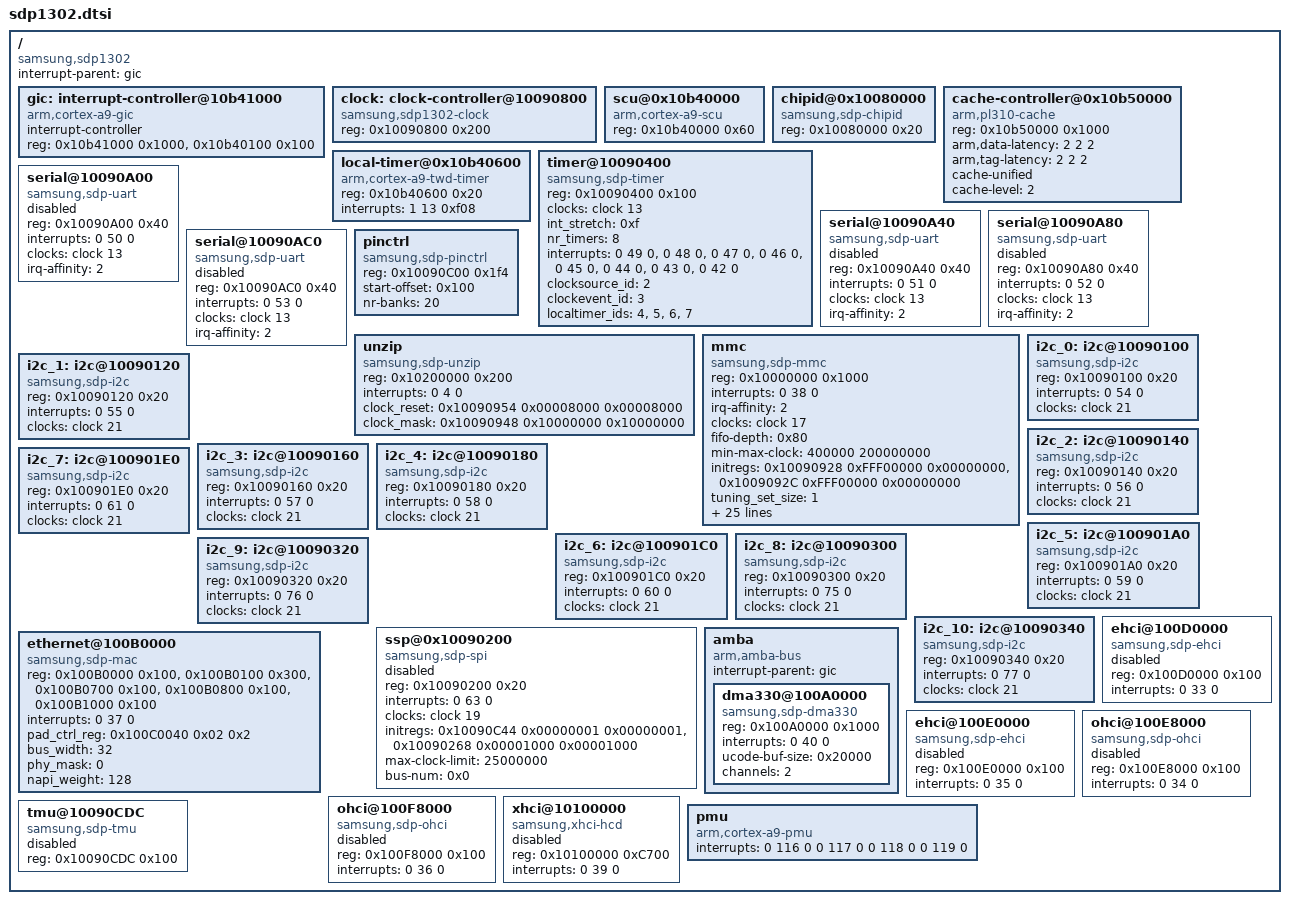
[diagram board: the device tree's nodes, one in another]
/*
 * Copyright (C) 2013 Samsung Electronics Co.Ltd
 *
 * This program is free software; you can redistribute it and/or modify
 * it under the terms of the GNU General Public License version 2 as
 * published by the Free Software Foundation.
 */

#include "sdp.dtsi"
#include "sdp1302-pinctrl.dtsi"

/ {
	compatible = "samsung,sdp1302";

	interrupt-parent = <&gic>;

	gic: interrupt-controller@10b41000 {
		compatible = "arm,cortex-a9-gic";
		interrupt-controller;
		#interrupt-cells = <3>;
		reg = <0x10b41000 0x1000>, <0x10b40100 0x100>;
	};

	clock: clock-controller@10090800 {
		compatible = "samsung,sdp1302-clock";
		reg = <0x10090800 0x200>;
		#clock-cells = <1>;
	};
        
	scu@0x10b40000 {
		compatible = "arm,cortex-a9-scu";
		reg = <0x10b40000 0x60>;
	};

	chipid@0x10080000 {
		compatible = "samsung,sdp-chipid";
		reg = <0x10080000 0x20>;
	};

	cache-controller@0x10b50000 {
		compatible = "arm,pl310-cache";
		reg = <0x10b50000 0x1000>;
		arm,data-latency = <2 2 2>;
		arm,tag-latency = <2 2 2>;
		cache-unified;
		cache-level = <2>;
	};

	local-timer@0x10b40600 {
		compatible = "arm,cortex-a9-twd-timer";
		reg = <0x10b40600 0x20>;
		interrupts = <1 13 0xf08>;
	};

	timer@10090400 {
		compatible = "samsung,sdp-timer";
		reg = <0x10090400 0x100>;
		clocks = <&clock 13>;
		clock-names = "apb_pclk";
		int_stretch = <0xf>;
		nr_timers = <8>;
		interrupts = <0 49 0>, <0 48 0>, <0 47 0>, <0 46 0>,
			<0 45 0>, <0 44 0>, <0 43 0>, <0 42 0>;
		clocksource_id = <2>;
		clockevent_id = <3>;
		localtimer_ids = <4>, <5>, <6>, <7>;
	};

	serial@10090A00 {
		compatible = "samsung,sdp-uart";
		reg = <0x10090A00 0x40>;
		interrupts = <0 50 0>;
		clocks = <&clock 13>;
		clock-names = "apb_pclk";
		irq-affinity = <2>;
		status = "disabled";
	};

	serial@10090A40 {
		compatible = "samsung,sdp-uart";
		reg = <0x10090A40 0x40>;
		interrupts = <0 51 0>;
		clocks = <&clock 13>;
		clock-names = "apb_pclk";
		irq-affinity = <2>;
		status = "disabled";
	};

	serial@10090A80 {
		compatible = "samsung,sdp-uart";
		reg = <0x10090A80 0x40>;
		interrupts = <0 52 0>;
		clocks = <&clock 13>;
		clock-names = "apb_pclk";
		irq-affinity = <2>;
		status = "disabled";
	};

	serial@10090AC0 {
		compatible = "samsung,sdp-uart";
		reg = <0x10090AC0 0x40>;
		interrupts = <0 53 0>;
		clocks = <&clock 13>;
		clock-names = "apb_pclk";
		irq-affinity = <2>;
		status = "disabled";
	};

	pinctrl {
		compatible = "samsung,sdp-pinctrl";
		reg = <0x10090C00 0x1f4>;
		start-offset = <0x100>;
		nr-banks = <20> ;
	};

	unzip {
		compatible = "samsung,sdp-unzip";
		reg = <0x10200000 0x200>;
		interrupts = < 0 4 0 >;
		clock_reset = <0x10090954 0x00008000 0x00008000>; 
		clock_mask = <0x10090948 0x10000000 0x10000000>;
	};
	
	mmc {
		compatible = "samsung,sdp-mmc";
		reg = <0x10000000 0x1000>;
		interrupts = <0 38 0>;
		irq-affinity = <2>;
		clocks = <&clock 17>;
		clock-names = "emmc_clk";
		fifo-depth = <0x80>;
		min-max-clock = <400000 200000000>;
		initregs =	<0x10090928 0xFFF00000 0x00000000>, <0x1009092C 0xFFF00000 0x00000000>;/* sam, drv bypass */

//		restoreregs =	<0x10090928 0xFFF00000>,/* eMMC drv delay register */
//						<0x1009092C 0xFFF00000>;/* eMMC sam delay register */

		/* eMMC Sampling Clock Delay Selection. 1.25ns ~ 5ns for HS200 */
		tuning_set_size = <1>;
		tuning_sam =	<0x1009092C 0xFFF00000 0x00800000>,
						<0x1009092C 0xFFF00000 0x04800000>,
						<0x1009092C 0xFFF00000 0x08800000>,
						<0x1009092C 0xFFF00000 0x0C800000>,
						<0x1009092C 0xFFF00000 0x01000000>,
						<0x1009092C 0xFFF00000 0x11000000>,
						<0x1009092C 0xFFF00000 0x21000000>,
						<0x1009092C 0xFFF00000 0x31000000>,
						<0x1009092C 0xFFF00000 0x01800000>,
						<0x1009092C 0xFFF00000 0x41800000>,
						<0x1009092C 0xFFF00000 0x81800000>,
						<0x1009092C 0xFFF00000 0xC1800000>,
						<0x1009092C 0xFFF00000 0x02000000>,
						<0x1009092C 0xFFF00000 0x42000000>;
						//<0x1009092C 0xFFF00000 0x82000000>,
						//<0x1009092C 0xFFF00000 0xC2000000>,
						//<0x1009092C 0xFFF00000 0x02800000>,
						//<0x1009092C 0xFFF00000 0x42800000>,
						//<0x1009092C 0xFFF00000 0x82800000>,
						//<0x1009092C 0xFFF00000 0xC2800000>;

		tuning_sam_hs200_default = <0x1009092C 0xFFF00000 0x00800000>;/* HS200 sampling defalut */
		tuning_drv_hs200_default = <0x10090928 0xFFF00000 0x04800000>;/* HS200 driving defalut for rev1 */
		fixup-golfs-input-clock;


		bus-width = <0x8>;
//		force-pio-mode;
		hw-reset;

		/* Host Caps */
		non-removable;
//		bus-width-test;
		highspeed;
//		sdr104;
		ddr50;
//		hs200;
		hs200-tuning;
	};

	i2c_0: i2c@10090100 {
		#address-cells = <1>;
		#size-cells = <0>;
		compatible = "samsung,sdp-i2c";
		reg = <0x10090100 0x20>;
		interrupts = <0 54 0>;
		clocks = <&clock 21>;
		clock-names = "rstn_i2c";
	};

	i2c_1: i2c@10090120 {
		#address-cells = <1>;
		#size-cells = <0>;
		compatible = "samsung,sdp-i2c";
		reg = <0x10090120 0x20>;
		interrupts = <0 55 0>;
		clocks = <&clock 21>;
		clock-names = "rstn_i2c";
	};

	i2c_2: i2c@10090140 {
		#address-cells = <1>;
		#size-cells = <0>;
		compatible = "samsung,sdp-i2c";
		reg = <0x10090140 0x20>;
		interrupts = <0 56 0>;
		clocks = <&clock 21>;
		clock-names = "rstn_i2c";
	};

	i2c_3: i2c@10090160 {
		#address-cells = <1>;
		#size-cells = <0>;
		compatible = "samsung,sdp-i2c";
		reg = <0x10090160 0x20>;
		interrupts = <0 57 0>;
		clocks = <&clock 21>;
		clock-names = "rstn_i2c";
	};

	i2c_4: i2c@10090180 {
		#address-cells = <1>;
		#size-cells = <0>;
		compatible = "samsung,sdp-i2c";
		reg = <0x10090180 0x20>;
		interrupts = <0 58 0>;
		clocks = <&clock 21>;
		clock-names = "rstn_i2c";
	};

	i2c_5: i2c@100901A0 {
		#address-cells = <1>;
		#size-cells = <0>;
		compatible = "samsung,sdp-i2c";
		reg = <0x100901A0 0x20>;
		interrupts = <0 59 0>;
		clocks = <&clock 21>;
		clock-names = "rstn_i2c";
	};

	i2c_6: i2c@100901C0 {
		#address-cells = <1>;
		#size-cells = <0>;
		compatible = "samsung,sdp-i2c";
		reg = <0x100901C0 0x20>;
		interrupts = <0 60 0>;
		clocks = <&clock 21>;
		clock-names = "rstn_i2c";
	};

	i2c_7: i2c@100901E0 {
		#address-cells = <1>;
		#size-cells = <0>;
		compatible = "samsung,sdp-i2c";
		reg = <0x100901E0 0x20>;
		interrupts = <0 61 0>;
		clocks = <&clock 21>;
		clock-names = "rstn_i2c";
	};

	i2c_8: i2c@10090300 {
		#address-cells = <1>;
		#size-cells = <0>;
		compatible = "samsung,sdp-i2c";
		reg = <0x10090300 0x20>;
		interrupts = <0 75 0>;
		clocks = <&clock 21>;
		clock-names = "rstn_i2c";
	};

	i2c_9: i2c@10090320 {
		#address-cells = <1>;
		#size-cells = <0>;
		compatible = "samsung,sdp-i2c";
		reg = <0x10090320 0x20>;
		interrupts = <0 76 0>;
		clocks = <&clock 21>;
		clock-names = "rstn_i2c";
	};

	i2c_10: i2c@10090340 {
		#address-cells = <1>;
		#size-cells = <0>;
		compatible = "samsung,sdp-i2c";
		reg = <0x10090340 0x20>;
		interrupts = <0 77 0>;
		clocks = <&clock 21>;
		clock-names = "rstn_i2c";
	};

	ssp@0x10090200 {
		status = "disable";
		compatible = "samsung,sdp-spi";
		reg = <0x10090200 0x20>;
		interrupts = <0 63 0>;
		clocks = <&clock 19>;
		clock-names = "spi_clk";

		#address-cells = <1>;
		#size-cells = <0>;

		initregs =	<0x10090C44 0x00000001 0x00000001>,/* SUB_FUNC_SEL_REG0 bit0 Pad SPI_SEL Selection */
					<0x10090268 0x00001000 0x00001000>;/* change MSPI to SSP */
		max-clock-limit = <25000000>;
		bus-num = <0x0>;
	};

	amba {
		#address-cells = <1>;
		#size-cells = <1>;
		compatible = "arm,amba-bus";
		interrupt-parent = <&gic>;
		ranges;

		dma330@100A0000 {
			status = "okay";
			compatible = "samsung,sdp-dma330", "arm,primecell";
			reg = <0x100A0000 0x1000>;
			interrupts = <0 40 0>;

			ucode-buf-size = <0x20000>;/*128kb*/
			channels = <2>;
		};
	};

	ethernet@100B0000 {
		compatible = "samsung,sdp-mac";
		reg = <0x100B0000 0x100>,
			<0x100B0100 0x300>,
			<0x100B0700 0x100>,
			<0x100B0800 0x100>,
			<0x100B1000 0x100>;
		interrupts = <0 37 0>;
		pad_ctrl_reg = <0x100C0040 0x02 0x2>;/* sstone sel */
		bus_width = <32>;
		phy_mask = <0>;
		napi_weight = <128>;
	};

	ehci@100D0000 {
		compatible = "samsung,sdp-ehci", "usb-ehci";
		reg = <0x100D0000 0x100>;
		interrupts = <0 33 0>;
		status = "disabled";
	};

	ehci@100E0000 {
		compatible = "samsung,sdp-ehci", "usb-ehci";
		reg = <0x100E0000 0x100>;
		interrupts = <0 35 0>;
		status = "disabled";
	};

	ohci@100E8000 {
		compatible = "samsung,sdp-ohci", "usb-ohci";
		reg = <0x100E8000 0x100>;
		interrupts = <0 34 0>;
		status = "disabled";
	};

	ohci@100F8000 {
		compatible = "samsung,sdp-ohci", "usb-ohci";
		reg = <0x100F8000 0x100>;
		interrupts = <0 36 0>;
		status = "disabled";
	};

	xhci@10100000 {
		compatible = "samsung,xhci-hcd", "usb-xhci";
		reg = <0x10100000 0xC700>;
		interrupts = <0 39 0>;
		status = "disabled";
	};

	tmu@10090CDC {
		compatible = "samsung,sdp-tmu";
		reg = <0x10090CDC 0x100>;
		status = "disabled";
	};

	pmu	{
		compatible = "arm,cortex-a9-pmu";
		interrupts = <0 116 0
				0 117 0
				0 118 0
				0 119 0>;
	};
};
